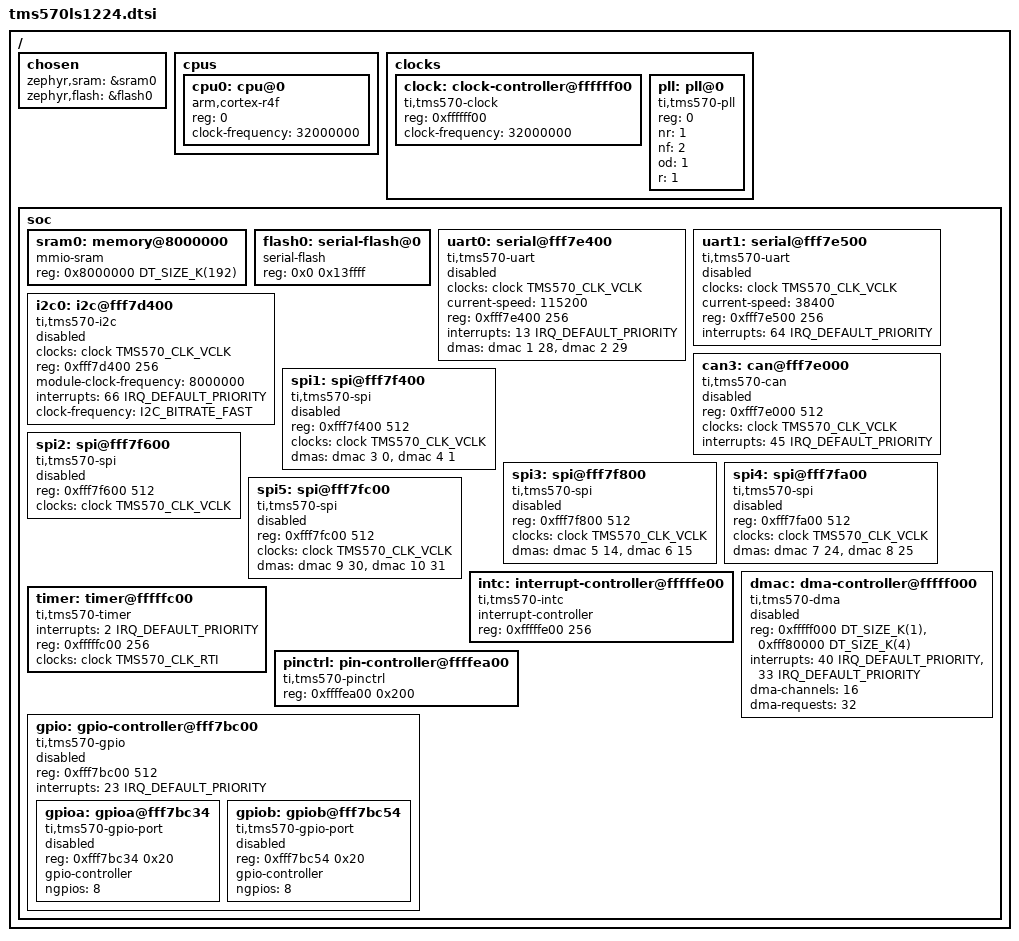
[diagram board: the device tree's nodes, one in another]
#include <arm/armv7-r.dtsi>
#include <mem.h>

#include <zephyr/dt-bindings/i2c/i2c.h>

#include <orbit/dt-bindings/interrupt_controller/tms570-intc.h>
#include <orbit/dt-bindings/pinctrl/tms570-pinctrl.h>
#include <orbit/dt-bindings/clock_control/clock_control_tms570.h>

/ {
    chosen {
        zephyr,sram = &sram0;
        zephyr,flash = &flash0;
    };

    cpus {
        #address-cells = <1>;
        #size-cells = <0>;

        cpu0: cpu@0 {
            compatible = "arm,cortex-r4f";
            reg = <0>;
            clock-frequency = <32000000>;
        };
    };

    clocks {
        #address-cells = <1>;
        #size-cells = <0>;
        
        clock: clock-controller@ffffff00 {
            compatible = "ti,tms570-clock";
            reg = <0xffffff00>;
            clock-frequency = <32000000>;
            #clock-cells = <1>;
        };

        pll: pll@0 {
            compatible = "ti,tms570-pll";
            reg = <0>;
            #clock-cells = <0>;

            nr = <1>;
            nf = <2>;
            od = <1>;
            r = <1>;
        };
    };

    soc {
        sram0: memory@8000000 {
            compatible = "mmio-sram";
            reg = <0x8000000 DT_SIZE_K(192)>;
        };

        flash0: serial-flash@0 {
            compatible = "serial-flash";
            reg = <0x0 0x13ffff>;
        };

        uart0: serial@fff7e400 {
            clocks = <&clock TMS570_CLK_VCLK>;
            compatible = "ti,tms570-uart";
            current-speed = <115200>;
            reg = <0xfff7e400 256>;
            status = "disabled";
            interrupts = <13 IRQ_DEFAULT_PRIORITY>;
            dmas = <&dmac 1 28>, <&dmac 2 29>;
            dma-names = "rx", "tx";
        };

        uart1: serial@fff7e500 {
            clocks = <&clock TMS570_CLK_VCLK>;
            compatible = "ti,tms570-uart";
            current-speed = <38400>;
            reg = <0xfff7e500 256>;
            status = "disabled";
            interrupts = <64 IRQ_DEFAULT_PRIORITY>;
        };

        i2c0: i2c@fff7d400 {
            clocks = <&clock TMS570_CLK_VCLK>;
            compatible = "ti,tms570-i2c";
            reg = <0xfff7d400 256>;
            module-clock-frequency = <8000000>;
            interrupts = <66 IRQ_DEFAULT_PRIORITY>;
            clock-frequency = <I2C_BITRATE_FAST>;
            status = "disabled";
            #address-cells = <1>;
            #size-cells = <0>;
        };

        can3: can@fff7e000 {
            compatible = "ti,tms570-can";
            status = "disabled";
            reg = <0xfff7e000 512>;
            clocks = <&clock TMS570_CLK_VCLK>;
            interrupts = <45 IRQ_DEFAULT_PRIORITY>;
        };

        spi1: spi@fff7f400 {
            compatible = "ti,tms570-spi";
            status = "disabled";
            #address-cells = <1>;
            #size-cells = <0>;
            reg = <0xfff7f400 512>;
            clocks = <&clock TMS570_CLK_VCLK>;
            dmas = <&dmac 3 0>, <&dmac 4 1>;
            dma-names = "rx", "tx";
        };

        spi2: spi@fff7f600 {
            compatible = "ti,tms570-spi";
            status = "disabled";
            #address-cells = <1>;
            #size-cells = <0>;
            reg = <0xfff7f600 512>;
            clocks = <&clock TMS570_CLK_VCLK>;
        };

        spi3: spi@fff7f800 {
            compatible = "ti,tms570-spi";
            status = "disabled";
            #address-cells = <1>;
            #size-cells = <0>;
            reg = <0xfff7f800 512>;
            clocks = <&clock TMS570_CLK_VCLK>;
            dmas = <&dmac 5 14>, <&dmac 6 15>;
            dma-names = "rx", "tx";
        };

        spi4: spi@fff7fa00 {
            compatible = "ti,tms570-spi";
            status = "disabled";
            #address-cells = <1>;
            #size-cells = <0>;
            reg = <0xfff7fa00 512>;
            clocks = <&clock TMS570_CLK_VCLK>;
            dmas = <&dmac 7 24>, <&dmac 8 25>;
            dma-names = "rx", "tx";
        };

        spi5: spi@fff7fc00 {
            compatible = "ti,tms570-spi";
            status = "disabled";
            #address-cells = <1>;
            #size-cells = <0>;
            reg = <0xfff7fc00 512>;
            clocks = <&clock TMS570_CLK_VCLK>;
            dmas = <&dmac 9 30>, <&dmac 10 31>;
            dma-names = "rx", "tx";
        };

        intc: interrupt-controller@fffffe00 {
            interrupt-controller;
            #interrupt-cells = <2>;
            reg = <0xfffffe00 256>;
            compatible = "ti,tms570-intc";
            status = "okay";
        };

        dmac: dma-controller@fffff000 {
            #dma-cells = <2>;
            compatible = "ti,tms570-dma";
            status = "disabled";
            reg = <0xfffff000 DT_SIZE_K(1)>, <0xfff80000 DT_SIZE_K(4)>;
            reg-names = "control", "packets";
            interrupts = <40 IRQ_DEFAULT_PRIORITY>, <33 IRQ_DEFAULT_PRIORITY>;
            dma-channels = <16>;
            dma-requests = <32>;
        };

        timer: timer@fffffc00 {
            compatible = "ti,tms570-timer";
            interrupts = <2 IRQ_DEFAULT_PRIORITY>;
            reg = <0xfffffc00 256>;
            clocks = <&clock TMS570_CLK_RTI>;
            status = "okay";
        };

        pinctrl: pin-controller@ffffea00 {
            compatible = "ti,tms570-pinctrl";
            reg = <0xffffea00 0x200>;
            status = "okay";
        };

        gpio: gpio-controller@fff7bc00 {
            compatible = "ti,tms570-gpio";
            status = "disabled";
            reg = <0xfff7bc00 512>;
            #address-cells = <1>;
            #size-cells = <1>;

            /* Currently only uses low-priority (B) interrupts */
            interrupts = <23 IRQ_DEFAULT_PRIORITY>;

            gpioa: gpioa@fff7bc34 {
                compatible = "ti,tms570-gpio-port";
                reg = <0xfff7bc34 0x20>;
                gpio-controller;
                #gpio-cells = <2>;
                ngpios = <8>;
                status = "disabled";
            };

            gpiob: gpiob@fff7bc54 {
                compatible = "ti,tms570-gpio-port";
                reg = <0xfff7bc54 0x20>;
                gpio-controller;
                #gpio-cells = <2>;
                ngpios = <8>;
                status = "disabled";
            };
        };
    };
};
